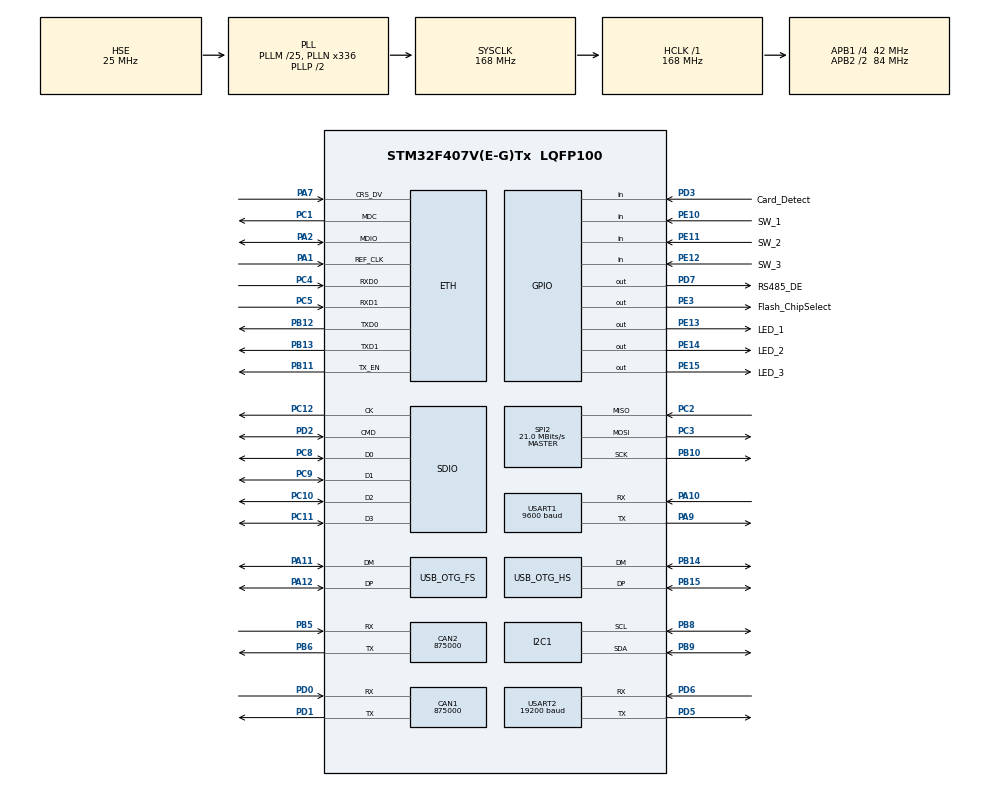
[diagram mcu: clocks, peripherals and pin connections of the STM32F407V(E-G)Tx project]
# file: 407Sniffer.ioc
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ADC1.Channel-0\#ChannelRegularConversion=ADC_CHANNEL_VBAT
ADC1.NbrOfConversionFlag=1
ADC1.Rank-0\#ChannelRegularConversion=1
ADC1.SamplingTime-0\#ChannelRegularConversion=ADC_SAMPLETIME_3CYCLES
ADC1.master=1
CAN1.CalculateBaudRate=875000
CAN1.CalculateTimeBit=1142
CAN1.CalculateTimeQuantum=380.95238095238096
CAN2.CalculateBaudRate=875000
CAN2.CalculateTimeBit=1142
CAN2.CalculateTimeQuantum=380.95238095238096
Dma.Request0=USART2_RX
Dma.Request1=SDIO
Dma.SDIO.1.Direction=DMA_PERIPH_TO_MEMORY
Dma.SDIO.1.FIFOMode=DMA_FIFOMODE_ENABLE
Dma.SDIO.1.FIFOThreshold=DMA_FIFO_THRESHOLD_FULL
Dma.SDIO.1.Instance=DMA2_Stream3
Dma.SDIO.1.MemBurst=DMA_MBURST_INC4
Dma.SDIO.1.MemDataAlignment=DMA_MDATAALIGN_WORD
Dma.SDIO.1.MemInc=DMA_MINC_ENABLE
Dma.SDIO.1.Mode=DMA_PFCTRL
Dma.SDIO.1.PeriphBurst=DMA_PBURST_INC4
Dma.SDIO.1.PeriphDataAlignment=DMA_PDATAALIGN_WORD
Dma.SDIO.1.PeriphInc=DMA_PINC_DISABLE
Dma.SDIO.1.Priority=DMA_PRIORITY_LOW
Dma.USART2_RX.0.Direction=DMA_PERIPH_TO_MEMORY
Dma.USART2_RX.0.FIFOMode=DMA_FIFOMODE_DISABLE
Dma.USART2_RX.0.Instance=DMA1_Stream5
Dma.USART2_RX.0.MemDataAlignment=DMA_MDATAALIGN_BYTE
Dma.USART2_RX.0.MemInc=DMA_MINC_ENABLE
Dma.USART2_RX.0.Mode=DMA_NORMAL
Dma.USART2_RX.0.PeriphDataAlignment=DMA_PDATAALIGN_BYTE
Dma.USART2_RX.0.PeriphInc=DMA_PINC_DISABLE
Dma.USART2_RX.0.Priority=DMA_PRIORITY_VERY_HIGH
ETH.MediaInterface=HAL_ETH_RMII_MODE
ETH.RxMode=ETH_RXPOLLING_MODE
FATFS.BSP.number=1
FATFS.USE_DMA_CODE_SD=1
FATFS._FS_TINY=0
FATFS._USE_LFN=3
FATFS0.BSP.STBoard=false
FATFS0.BSP.api=Unknown
FATFS0.BSP.instance=PD3
FATFS0.BSP.ip=GPIO
FATFS0.BSP.mode=Input
FATFS0.BSP.name=Detect_SDIO
FATFS0.BSP.solution=PD3
I2C1.I2C_Mode=I2C_Standard
IWDG.Prescaler=IWDG_PRESCALER_64
IWDG.Reload=2499
Mcu.Family=STM32F4
Mcu.Name=STM32F407V(E-G)Tx
Mcu.Package=LQFP100
NVIC.DMA1_Stream5_IRQn=true\:0\:0\:false\:false\:true\:false\:true\:true
NVIC.DMA2_Stream3_IRQn=true\:0\:0\:false\:false\:true\:false\:true\:true
NVIC.OTG_FS_IRQn=true\:0\:0\:false\:false\:true\:false\:true\:true
NVIC.OTG_HS_IRQn=true\:0\:0\:false\:false\:true\:false\:true\:true
NVIC.PriorityGroup=NVIC_PRIORITYGROUP_4
NVIC.SDIO_IRQn=true\:0\:0\:false\:false\:true\:true\:true\:true
NVIC.TIM2_IRQn=true\:0\:0\:false\:false\:true\:true\:true\:true
PA1.Mode=RMII
PA1.Signal=ETH_REF_CLK
PA10.Mode=Asynchronous
PA10.Signal=USART1_RX
PA11.Mode=Device_Only
PA11.Signal=USB_OTG_FS_DM
PA12.Mode=Device_Only
PA12.Signal=USB_OTG_FS_DP
PA2.Mode=RMII
PA2.Signal=ETH_MDIO
PA7.Mode=RMII
PA7.Signal=ETH_CRS_DV
PA9.Mode=Asynchronous
PA9.Signal=USART1_TX
PB10.Mode=Full_Duplex_Master
PB10.Signal=SPI2_SCK
PB11.Mode=RMII
PB11.Signal=ETH_TX_EN
PB12.Mode=RMII
PB12.Signal=ETH_TXD0
PB13.Mode=RMII
PB13.Signal=ETH_TXD1
PB14.Mode=Host_FS
PB14.Signal=USB_OTG_HS_DM
PB15.Mode=Host_FS
PB15.Signal=USB_OTG_HS_DP
PB5.Mode=CAN_Activate
PB5.Signal=CAN2_RX
PB6.Mode=CAN_Activate
PB6.Signal=CAN2_TX
PB8.Mode=I2C
PB8.Signal=I2C1_SCL
PB9.Mode=I2C
PB9.Signal=I2C1_SDA
PC1.Mode=RMII
PC1.Signal=ETH_MDC
PC10.Mode=SD_4_bits_Wide_bus
PC10.Signal=SDIO_D2
PC11.Mode=SD_4_bits_Wide_bus
PC11.Signal=SDIO_D3
PC12.Mode=SD_4_bits_Wide_bus
PC12.Signal=SDIO_CK
PC14-OSC32_IN.Mode=LSE-External-Oscillator
PC14-OSC32_IN.Signal=RCC_OSC32_IN
PC15-OSC32_OUT.Mode=LSE-External-Oscillator
PC15-OSC32_OUT.Signal=RCC_OSC32_OUT
PC2.Mode=Full_Duplex_Master
PC2.Signal=SPI2_MISO
PC3.Mode=Full_Duplex_Master
PC3.Signal=SPI2_MOSI
PC4.Mode=RMII
PC4.Signal=ETH_RXD0
PC5.Mode=RMII
PC5.Signal=ETH_RXD1
PC8.Mode=SD_4_bits_Wide_bus
PC8.Signal=SDIO_D0
PC9.Mode=SD_4_bits_Wide_bus
PC9.Signal=SDIO_D1
PD0.Mode=CAN_Activate
PD0.Signal=CAN1_RX
PD1.Mode=CAN_Activate
PD1.Signal=CAN1_TX
PD2.Mode=SD_4_bits_Wide_bus
PD2.Signal=SDIO_CMD
PD3.GPIO_Label=Card_Detect
PD3.Signal=GPIO_Input
PD5.Mode=Asynchronous
PD5.Signal=USART2_TX
PD6.Mode=Asynchronous
PD6.Signal=USART2_RX
PD7.GPIO_Label=RS485_DE
PD7.GPIO_Speed=GPIO_SPEED_FREQ_VERY_HIGH
PD7.Signal=GPIO_Output
PE10.GPIO_Label=SW_1
PE10.Signal=GPIO_Input
PE11.GPIO_Label=SW_2
PE11.Signal=GPIO_Input
PE12.GPIO_Label=SW_3
PE12.Signal=GPIO_Input
PE13.GPIO_Label=LED_1
PE13.PinState=GPIO_PIN_SET
PE13.Signal=GPIO_Output
PE14.GPIO_Label=LED_2
PE14.PinState=GPIO_PIN_SET
PE14.Signal=GPIO_Output
PE15.GPIO_Label=LED_3
PE15.PinState=GPIO_PIN_SET
PE15.Signal=GPIO_Output
PE3.GPIO_Label=Flash_ChipSelect
PE3.PinState=GPIO_PIN_SET
PE3.Signal=GPIO_Output
PH0-OSC_IN.Mode=HSE-External-Oscillator
PH0-OSC_IN.Signal=RCC_OSC_IN
PH1-OSC_OUT.Mode=HSE-External-Oscillator
PH1-OSC_OUT.Signal=RCC_OSC_OUT
ProjectManager.HeapSize=0x200
ProjectManager.StackSize=0x400
ProjectManager.TargetToolchain=STM32CubeIDE
RCC.48MHZClocksFreq_Value=48000000
RCC.AHBFreq_Value=168000000
RCC.APB1CLKDivider=RCC_HCLK_DIV4
RCC.APB1Freq_Value=42000000
RCC.APB1TimFreq_Value=84000000
RCC.APB2CLKDivider=RCC_HCLK_DIV2
RCC.APB2Freq_Value=84000000
RCC.APB2TimFreq_Value=168000000
RCC.CortexFreq_Value=168000000
RCC.EnbaleCSS=true
RCC.HCLKFreq_Value=168000000
RCC.HSE_VALUE=25000000
RCC.HSI_VALUE=16000000
RCC.PLLM=25
RCC.PLLN=336
RCC.PLLQ=7
RCC.RCC_RTC_Clock_Source=RCC_RTCCLKSOURCE_LSE
RCC.SYSCLKFreq_VALUE=168000000
RCC.SYSCLKSource=RCC_SYSCLKSOURCE_PLLCLK
RCC.VCOOutputFreq_Value=336000000
RTC.WeekDay=RTC_WEEKDAY_THURSDAY
RTC.Year=26
SDIO.ClockDiv=2
SDIO.HardwareFlowControl=SDIO_HARDWARE_FLOW_CONTROL_ENABLE
SPI2.CalculateBaudRate=21.0 MBits/s
SPI2.Direction=SPI_DIRECTION_2LINES
SPI2.Mode=SPI_MODE_MASTER
SPI2.VirtualType=VM_MASTER
TIM2.AutoReloadPreload=TIM_AUTORELOAD_PRELOAD_DISABLE
TIM2.ClockDivision=TIM_CLOCKDIVISION_DIV1
TIM2.Period=999
TIM2.Prescaler=83
USART1.BaudRate=9600
USART1.VirtualMode=VM_ASYNC
USART2.BaudRate=19200
USART2.VirtualMode=VM_ASYNC
USB_DEVICE.CLASS_NAME_FS=CDC
USB_DEVICE.MANUFACTURER_STRING-CDC_FS=AhmedMahdy
USB_DEVICE.PRODUCT_STRING_CDC_FS=AhmedMahdyDev
USB_DEVICE.VID-CDC_FS=9200
USB_DEVICE.VirtualMode-CDC_FS=Cdc
USB_DEVICE.VirtualModeFS=Cdc_FS
USB_HOST.SW_VBUS_DRIVE_MSC_HS=true
USB_HOST.USBH_HandleTypeDef-MSC_HS=hUsbHostHS
USB_HOST.VirtualModeHS=Msc
USB_OTG_FS.VirtualMode=Device_Only
USB_OTG_HS.VirtualMode-Host_FS=Host_FS
VP_ADC1_Vbat_Input.Mode=IN-Vbat
VP_FATFS_VS_SDIO.Mode=SDIO
VP_IWDG_VS_IWDG.Mode=IWDG_Activate
VP_RTC_VS_RTC_Activate.Mode=RTC_Enabled
VP_RTC_VS_RTC_Calendar.Mode=RTC_Calendar
VP_TIM2_VS_ClockSourceINT.Mode=Internal
VP_USB_DEVICE_VS_USB_DEVICE_CDC_FS.Mode=CDC_FS
VP_USB_HOST_VS_USB_HOST_MSC_HS.Mode=MSC_HS
board=custom

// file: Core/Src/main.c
/* USER CODE BEGIN Header */
/**
  ******************************************************************************
  * @file           : main.c
  * @brief          : Main program body
  ******************************************************************************
  * @attention
  *
  * Copyright (c) 2026 STMicroelectronics.
  * All rights reserved.
  *
  * This software is licensed under terms that can be found in the LICENSE file
  * in the root directory of this software component.
  * If no LICENSE file comes with this software, it is provided AS-IS.
  *
  ******************************************************************************
  */
/* USER CODE END Header */
#include "main.h"
#include "string.h"
#include "fatfs.h"
#include "usb_device.h"
#include "usb_host.h"

/* USER CODE BEGIN Includes */
#include "mainHelper.h"
/* USER CODE END Includes */

ETH_TxPacketConfig TxConfig;
ETH_DMADescTypeDef  DMARxDscrTab[ETH_RX_DESC_CNT]; /* Ethernet Rx DMA Descriptors */
ETH_DMADescTypeDef  DMATxDscrTab[ETH_TX_DESC_CNT]; /* Ethernet Tx DMA Descriptors */

ADC_HandleTypeDef hadc1;

CAN_HandleTypeDef hcan1;
CAN_HandleTypeDef hcan2;

ETH_HandleTypeDef heth;

I2C_HandleTypeDef hi2c1;

IWDG_HandleTypeDef hiwdg;

RTC_HandleTypeDef hrtc;

SD_HandleTypeDef hsd;
DMA_HandleTypeDef hdma_sdio;

SPI_HandleTypeDef hspi2;

TIM_HandleTypeDef htim2;

UART_HandleTypeDef huart1;
UART_HandleTypeDef huart2;
DMA_HandleTypeDef hdma_usart2_rx;

void SystemClock_Config(void);
static void MX_GPIO_Init(void);
static void MX_DMA_Init(void);
static void MX_ADC1_Init(void);
static void MX_CAN1_Init(void);
static void MX_CAN2_Init(void);
static void MX_ETH_Init(void);
static void MX_I2C1_Init(void);
static void MX_RTC_Init(void);
static void MX_SDIO_SD_Init(void);
static void MX_SPI2_Init(void);
static void MX_USART1_UART_Init(void);
static void MX_USART2_UART_Init(void);
static void MX_TIM2_Init(void);
static void MX_IWDG_Init(void);
void MX_USB_HOST_Process(void);

int main(void)
{

  /* MCU Configuration--------------------------------------------------------*/

  /* Reset of all peripherals, Initializes the Flash interface and the Systick. */
  HAL_Init();

  /* Configure the system clock */
  SystemClock_Config();

  /* Initialize all configured peripherals */
  MX_GPIO_Init();
  MX_DMA_Init();
  MX_ADC1_Init();
  MX_CAN1_Init();
  MX_CAN2_Init();
  MX_ETH_Init();
  MX_I2C1_Init();
  MX_RTC_Init();
  MX_SDIO_SD_Init();
  MX_SPI2_Init();
  MX_USART1_UART_Init();
  MX_USART2_UART_Init();
  MX_FATFS_Init();
  MX_USB_DEVICE_Init();
  MX_USB_HOST_Init();
  MX_TIM2_Init();
  MX_IWDG_Init();
  /* USER CODE BEGIN 2 */
  vMainInitFunc();
  vMainLoopFunc();
  /* USER CODE END 2 */

  /* Infinite loop */
  while (1)
  {
    MX_USB_HOST_Process();

  }
}

void SystemClock_Config(void)
{
  RCC_OscInitTypeDef RCC_OscInitStruct = {0};
  RCC_ClkInitTypeDef RCC_ClkInitStruct = {0};

  /** Configure the main internal regulator output voltage
  */
  __HAL_RCC_PWR_CLK_ENABLE();
  __HAL_PWR_VOLTAGESCALING_CONFIG(PWR_REGULATOR_VOLTAGE_SCALE1);

  /** Initializes the RCC Oscillators according to the specified parameters
  * in the RCC_OscInitTypeDef structure.
  */
  RCC_OscInitStruct.OscillatorType = RCC_OSCILLATORTYPE_LSI|RCC_OSCILLATORTYPE_HSE
                              |RCC_OSCILLATORTYPE_LSE;
  RCC_OscInitStruct.HSEState = RCC_HSE_ON;
  RCC_OscInitStruct.LSEState = RCC_LSE_ON;
  RCC_OscInitStruct.LSIState = RCC_LSI_ON;
  RCC_OscInitStruct.PLL.PLLState = RCC_PLL_ON;
  RCC_OscInitStruct.PLL.PLLSource = RCC_PLLSOURCE_HSE;
  RCC_OscInitStruct.PLL.PLLM = 25;
  RCC_OscInitStruct.PLL.PLLN = 336;
  RCC_OscInitStruct.PLL.PLLP = RCC_PLLP_DIV2;
  RCC_OscInitStruct.PLL.PLLQ = 7;
  if (HAL_RCC_OscConfig(&RCC_OscInitStruct) != HAL_OK)
  {
    Error_Handler();
  }

  /** Initializes the CPU, AHB and APB buses clocks
  */
  RCC_ClkInitStruct.ClockType = RCC_CLOCKTYPE_HCLK|RCC_CLOCKTYPE_SYSCLK
                              |RCC_CLOCKTYPE_PCLK1|RCC_CLOCKTYPE_PCLK2;
  RCC_ClkInitStruct.SYSCLKSource = RCC_SYSCLKSOURCE_PLLCLK;
  RCC_ClkInitStruct.AHBCLKDivider = RCC_SYSCLK_DIV1;
  RCC_ClkInitStruct.APB1CLKDivider = RCC_HCLK_DIV4;
  RCC_ClkInitStruct.APB2CLKDivider = RCC_HCLK_DIV2;

  if (HAL_RCC_ClockConfig(&RCC_ClkInitStruct, FLASH_LATENCY_5) != HAL_OK)
  {
    Error_Handler();
  }

  /** Enables the Clock Security System
  */
  HAL_RCC_EnableCSS();
}

static void MX_ADC1_Init(void)
{

  ADC_ChannelConfTypeDef sConfig = {0};

  /** Configure the global features of the ADC (Clock, Resolution, Data Alignment and number of conversion)
  */
  hadc1.Instance = ADC1;
  hadc1.Init.ClockPrescaler = ADC_CLOCK_SYNC_PCLK_DIV4;
  hadc1.Init.Resolution = ADC_RESOLUTION_12B;
  hadc1.Init.ScanConvMode = DISABLE;
  hadc1.Init.ContinuousConvMode = DISABLE;
  hadc1.Init.DiscontinuousConvMode = DISABLE;
  hadc1.Init.ExternalTrigConvEdge = ADC_EXTERNALTRIGCONVEDGE_NONE;
  hadc1.Init.ExternalTrigConv = ADC_SOFTWARE_START;
  hadc1.Init.DataAlign = ADC_DATAALIGN_RIGHT;
  hadc1.Init.NbrOfConversion = 1;
  hadc1.Init.DMAContinuousRequests = DISABLE;
  hadc1.Init.EOCSelection = ADC_EOC_SINGLE_CONV;
  if (HAL_ADC_Init(&hadc1) != HAL_OK)
  {
    Error_Handler();
  }

  /** Configure for the selected ADC regular channel its corresponding rank in the sequencer and its sample time.
  */
  sConfig.Channel = ADC_CHANNEL_VBAT;
  sConfig.Rank = 1;
  sConfig.SamplingTime = ADC_SAMPLETIME_3CYCLES;
  if (HAL_ADC_ConfigChannel(&hadc1, &sConfig) != HAL_OK)
  {
    Error_Handler();
  }

}

static void MX_CAN1_Init(void)
{

  hcan1.Instance = CAN1;
  hcan1.Init.Prescaler = 16;
  hcan1.Init.Mode = CAN_MODE_NORMAL;
  hcan1.Init.SyncJumpWidth = CAN_SJW_1TQ;
  hcan1.Init.TimeSeg1 = CAN_BS1_1TQ;
  hcan1.Init.TimeSeg2 = CAN_BS2_1TQ;
  hcan1.Init.TimeTriggeredMode = DISABLE;
  hcan1.Init.AutoBusOff = DISABLE;
  hcan1.Init.AutoWakeUp = DISABLE;
  hcan1.Init.AutoRetransmission = DISABLE;
  hcan1.Init.ReceiveFifoLocked = DISABLE;
  hcan1.Init.TransmitFifoPriority = DISABLE;
  if (HAL_CAN_Init(&hcan1) != HAL_OK)
  {
    Error_Handler();
  }

}

static void MX_CAN2_Init(void)
{

  hcan2.Instance = CAN2;
  hcan2.Init.Prescaler = 16;
  hcan2.Init.Mode = CAN_MODE_NORMAL;
  hcan2.Init.SyncJumpWidth = CAN_SJW_1TQ;
  hcan2.Init.TimeSeg1 = CAN_BS1_1TQ;
  hcan2.Init.TimeSeg2 = CAN_BS2_1TQ;
  hcan2.Init.TimeTriggeredMode = DISABLE;
  hcan2.Init.AutoBusOff = DISABLE;
  hcan2.Init.AutoWakeUp = DISABLE;
  hcan2.Init.AutoRetransmission = DISABLE;
  hcan2.Init.ReceiveFifoLocked = DISABLE;
  hcan2.Init.TransmitFifoPriority = DISABLE;
  if (HAL_CAN_Init(&hcan2) != HAL_OK)
  {
    Error_Handler();
  }

}

static void MX_ETH_Init(void)
{

   static uint8_t MACAddr[6];

  heth.Instance = ETH;
  MACAddr[0] = 0x00;
  MACAddr[1] = 0x80;
  MACAddr[2] = 0xE1;
  MACAddr[3] = 0x00;
  MACAddr[4] = 0x00;
  MACAddr[5] = 0x00;
  heth.Init.MACAddr = &MACAddr[0];
  heth.Init.MediaInterface = HAL_ETH_RMII_MODE;
  heth.Init.TxDesc = DMATxDscrTab;
  heth.Init.RxDesc = DMARxDscrTab;
  heth.Init.RxBuffLen = 1524;

  if (HAL_ETH_Init(&heth) != HAL_OK)
  {
    Error_Handler();
  }

  memset(&TxConfig, 0 , sizeof(ETH_TxPacketConfig));
  TxConfig.Attributes = ETH_TX_PACKETS_FEATURES_CSUM | ETH_TX_PACKETS_FEATURES_CRCPAD;
  TxConfig.ChecksumCtrl = ETH_CHECKSUM_IPHDR_PAYLOAD_INSERT_PHDR_CALC;
  TxConfig.CRCPadCtrl = ETH_CRC_PAD_INSERT;

}

static void MX_I2C1_Init(void)
{

  hi2c1.Instance = I2C1;
  hi2c1.Init.ClockSpeed = 100000;
  hi2c1.Init.DutyCycle = I2C_DUTYCYCLE_2;
  hi2c1.Init.OwnAddress1 = 0;
  hi2c1.Init.AddressingMode = I2C_ADDRESSINGMODE_7BIT;
  hi2c1.Init.DualAddressMode = I2C_DUALADDRESS_DISABLE;
  hi2c1.Init.OwnAddress2 = 0;
  hi2c1.Init.GeneralCallMode = I2C_GENERALCALL_DISABLE;
  hi2c1.Init.NoStretchMode = I2C_NOSTRETCH_DISABLE;
  if (HAL_I2C_Init(&hi2c1) != HAL_OK)
  {
    Error_Handler();
  }

}

static void MX_IWDG_Init(void)
{

  hiwdg.Instance = IWDG;
  hiwdg.Init.Prescaler = IWDG_PRESCALER_64;
  hiwdg.Init.Reload = 2499;
  if (HAL_IWDG_Init(&hiwdg) != HAL_OK)
  {
    Error_Handler();
  }

}

static void MX_RTC_Init(void)
{

  RTC_TimeTypeDef sTime = {0};
  RTC_DateTypeDef sDate = {0};

  /** Initialize RTC Only
  */
  hrtc.Instance = RTC;
  hrtc.Init.HourFormat = RTC_HOURFORMAT_24;
  hrtc.Init.AsynchPrediv = 127;
  hrtc.Init.SynchPrediv = 255;
  hrtc.Init.OutPut = RTC_OUTPUT_DISABLE;
  hrtc.Init.OutPutPolarity = RTC_OUTPUT_POLARITY_HIGH;
  hrtc.Init.OutPutType = RTC_OUTPUT_TYPE_OPENDRAIN;
  if (HAL_RTC_Init(&hrtc) != HAL_OK)
  {
    Error_Handler();
  }

  /* USER CODE BEGIN Check_RTC_BKUP */
  if(HAL_RTCEx_BKUPRead(&hrtc, RTC_BKP_DR0) != 0xADAD){

  /* USER CODE END Check_RTC_BKUP */

  /** Initialize RTC and set the Time and Date
  */
  sTime.Hours = 0x0;
  sTime.Minutes = 0x0;
  sTime.Seconds = 0x0;
  sTime.DayLightSaving = RTC_DAYLIGHTSAVING_NONE;
  sTime.StoreOperation = RTC_STOREOPERATION_RESET;
  if (HAL_RTC_SetTime(&hrtc, &sTime, RTC_FORMAT_BCD) != HAL_OK)
  {
    Error_Handler();
  }
  sDate.WeekDay = RTC_WEEKDAY_THURSDAY;
  sDate.Month = RTC_MONTH_JANUARY;
  sDate.Date = 0x1;
  sDate.Year = 0x26;

  if (HAL_RTC_SetDate(&hrtc, &sDate, RTC_FORMAT_BCD) != HAL_OK)
  {
    Error_Handler();
  }
  /* USER CODE BEGIN RTC_Init 2 */
  HAL_RTCEx_BKUPWrite(&hrtc, RTC_BKP_DR0, 0xADAD);
  }
  /* USER CODE END RTC_Init 2 */

}

static void MX_SDIO_SD_Init(void)
{

  hsd.Instance = SDIO;
  hsd.Init.ClockEdge = SDIO_CLOCK_EDGE_RISING;
  hsd.Init.ClockBypass = SDIO_CLOCK_BYPASS_DISABLE;
  hsd.Init.ClockPowerSave = SDIO_CLOCK_POWER_SAVE_DISABLE;
  hsd.Init.BusWide = SDIO_BUS_WIDE_1B;
  hsd.Init.HardwareFlowControl = SDIO_HARDWARE_FLOW_CONTROL_ENABLE;
  hsd.Init.ClockDiv = 2; // with this device works with 21Mhz ( 84 / ( ClockDiv + 2) )
  /* USER CODE BEGIN SDIO_Init 2 */
  // hsd.Init.ClockDiv = 2; // with this device works with 21Mhz ( 84 / ( ClockDiv + 2) )
  /* USER CODE END SDIO_Init 2 */

}

static void MX_SPI2_Init(void)
{

  /* SPI2 parameter configuration*/
  hspi2.Instance = SPI2;
  hspi2.Init.Mode = SPI_MODE_MASTER;
  hspi2.Init.Direction = SPI_DIRECTION_2LINES;
  hspi2.Init.DataSize = SPI_DATASIZE_8BIT;
  hspi2.Init.CLKPolarity = SPI_POLARITY_LOW;
  hspi2.Init.CLKPhase = SPI_PHASE_1EDGE;
  hspi2.Init.NSS = SPI_NSS_SOFT;
  hspi2.Init.BaudRatePrescaler = SPI_BAUDRATEPRESCALER_2;
  hspi2.Init.FirstBit = SPI_FIRSTBIT_MSB;
  hspi2.Init.TIMode = SPI_TIMODE_DISABLE;
  hspi2.Init.CRCCalculation = SPI_CRCCALCULATION_DISABLE;
  hspi2.Init.CRCPolynomial = 10;
  if (HAL_SPI_Init(&hspi2) != HAL_OK)
  {
    Error_Handler();
  }

}

static void MX_TIM2_Init(void)
{

  TIM_ClockConfigTypeDef sClockSourceConfig = {0};
  TIM_MasterConfigTypeDef sMasterConfig = {0};

  htim2.Instance = TIM2;
  htim2.Init.Prescaler = 83;
  htim2.Init.CounterMode = TIM_COUNTERMODE_UP;
  htim2.Init.Period = 999;
  htim2.Init.ClockDivision = TIM_CLOCKDIVISION_DIV1;
  htim2.Init.AutoReloadPreload = TIM_AUTORELOAD_PRELOAD_DISABLE;
  if (HAL_TIM_Base_Init(&htim2) != HAL_OK)
  {
    Error_Handler();
  }
  sClockSourceConfig.ClockSource = TIM_CLOCKSOURCE_INTERNAL;
  if (HAL_TIM_ConfigClockSource(&htim2, &sClockSourceConfig) != HAL_OK)
  {
    Error_Handler();
  }
  sMasterConfig.MasterOutputTrigger = TIM_TRGO_RESET;
  sMasterConfig.MasterSlaveMode = TIM_MASTERSLAVEMODE_DISABLE;
  if (HAL_TIMEx_MasterConfigSynchronization(&htim2, &sMasterConfig) != HAL_OK)
  {
    Error_Handler();
  }

}

static void MX_USART1_UART_Init(void)
{

  huart1.Instance = USART1;
  huart1.Init.BaudRate = 9600;
  huart1.Init.WordLength = UART_WORDLENGTH_8B;
  huart1.Init.StopBits = UART_STOPBITS_1;
  huart1.Init.Parity = UART_PARITY_NONE;
  huart1.Init.Mode = UART_MODE_TX_RX;
  huart1.Init.HwFlowCtl = UART_HWCONTROL_NONE;
  huart1.Init.OverSampling = UART_OVERSAMPLING_16;
  if (HAL_UART_Init(&huart1) != HAL_OK)
  {
    Error_Handler();
  }

}

static void MX_USART2_UART_Init(void)
{

  huart2.Instance = USART2;
  huart2.Init.BaudRate = 19200;
  huart2.Init.WordLength = UART_WORDLENGTH_8B;
  huart2.Init.StopBits = UART_STOPBITS_1;
  huart2.Init.Parity = UART_PARITY_NONE;
  huart2.Init.Mode = UART_MODE_TX_RX;
  huart2.Init.HwFlowCtl = UART_HWCONTROL_NONE;
  huart2.Init.OverSampling = UART_OVERSAMPLING_16;
  if (HAL_UART_Init(&huart2) != HAL_OK)
  {
    Error_Handler();
  }

}

static void MX_DMA_Init(void)
{

  /* DMA controller clock enable */
  __HAL_RCC_DMA1_CLK_ENABLE();
  __HAL_RCC_DMA2_CLK_ENABLE();

  /* DMA interrupt init */
  /* DMA1_Stream5_IRQn interrupt configuration */
  HAL_NVIC_SetPriority(DMA1_Stream5_IRQn, 0, 0);
  HAL_NVIC_EnableIRQ(DMA1_Stream5_IRQn);
  /* DMA2_Stream3_IRQn interrupt configuration */
  HAL_NVIC_SetPriority(DMA2_Stream3_IRQn, 0, 0);
  HAL_NVIC_EnableIRQ(DMA2_Stream3_IRQn);

}

static void MX_GPIO_Init(void)
{
  GPIO_InitTypeDef GPIO_InitStruct = {0};

  /* GPIO Ports Clock Enable */
  __HAL_RCC_GPIOE_CLK_ENABLE();
  __HAL_RCC_GPIOC_CLK_ENABLE();
  __HAL_RCC_GPIOH_CLK_ENABLE();
  __HAL_RCC_GPIOA_CLK_ENABLE();
  __HAL_RCC_GPIOB_CLK_ENABLE();
  __HAL_RCC_GPIOD_CLK_ENABLE();

  /*Configure GPIO pin Output Level */
  HAL_GPIO_WritePin(GPIOE, Flash_ChipSelect_Pin|LED_1_Pin|LED_2_Pin|LED_3_Pin, GPIO_PIN_SET);

  /*Configure GPIO pin Output Level */
  HAL_GPIO_WritePin(RS485_DE_GPIO_Port, RS485_DE_Pin, GPIO_PIN_RESET);

  /*Configure GPIO pins : Flash_ChipSelect_Pin LED_1_Pin LED_2_Pin LED_3_Pin */
  GPIO_InitStruct.Pin = Flash_ChipSelect_Pin|LED_1_Pin|LED_2_Pin|LED_3_Pin;
  GPIO_InitStruct.Mode = GPIO_MODE_OUTPUT_PP;
  GPIO_InitStruct.Pull = GPIO_NOPULL;
  GPIO_InitStruct.Speed = GPIO_SPEED_FREQ_LOW;
  HAL_GPIO_Init(GPIOE, &GPIO_InitStruct);

  /*Configure GPIO pins : SW_1_Pin SW_2_Pin SW_3_Pin */
  GPIO_InitStruct.Pin = SW_1_Pin|SW_2_Pin|SW_3_Pin;
  GPIO_InitStruct.Mode = GPIO_MODE_INPUT;
  GPIO_InitStruct.Pull = GPIO_NOPULL;
  HAL_GPIO_Init(GPIOE, &GPIO_InitStruct);

  /*Configure GPIO pin : Card_Detect_Pin */
  GPIO_InitStruct.Pin = Card_Detect_Pin;
  GPIO_InitStruct.Mode = GPIO_MODE_INPUT;
  GPIO_InitStruct.Pull = GPIO_NOPULL;
  HAL_GPIO_Init(Card_Detect_GPIO_Port, &GPIO_InitStruct);

  /*Configure GPIO pin : RS485_DE_Pin */
  GPIO_InitStruct.Pin = RS485_DE_Pin;
  GPIO_InitStruct.Mode = GPIO_MODE_OUTPUT_PP;
  GPIO_InitStruct.Pull = GPIO_NOPULL;
  GPIO_InitStruct.Speed = GPIO_SPEED_FREQ_VERY_HIGH;
  HAL_GPIO_Init(RS485_DE_GPIO_Port, &GPIO_InitStruct);

}

void Error_Handler(void)
{
  __disable_irq();
  while (1)
  {
  }
}
